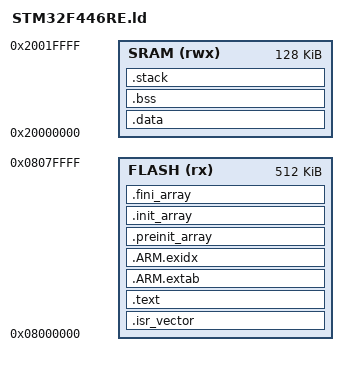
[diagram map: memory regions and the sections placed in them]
/*
 * STM32F446RE linker script for MAMBA-NIKE KAT test.
 *
 * Memory layout:
 *   FLASH: 512 KB (0x08000000)
 *   SRAM:  128 KB (0x20000000)
 *
 * Heap: 0 KB (all memory via static pools — no malloc on bare metal)
 * Stack: 8 KB
 */

MEMORY
{
    FLASH (rx) : ORIGIN = 0x08000000, LENGTH = 512K
    SRAM  (rwx): ORIGIN = 0x20000000, LENGTH = 128K
}

_estack = ORIGIN(SRAM) + LENGTH(SRAM);

SECTIONS
{
    .isr_vector :
    {
        KEEP(*(.isr_vector))
    } >FLASH

    .text :
    {
        *(.text*)
        *(.rodata*)
        KEEP(*(.init))
        KEEP(*(.fini))
    } >FLASH

    .ARM.extab : { *(.ARM.extab* .gnu.linkonce.armextab.*) } >FLASH
    .ARM.exidx : { *(.ARM.exidx*) } >FLASH

    .preinit_array :
    {
        PROVIDE_HIDDEN(__preinit_array_start = .);
        KEEP(*(.preinit_array*))
        PROVIDE_HIDDEN(__preinit_array_end = .);
    } >FLASH

    .init_array :
    {
        PROVIDE_HIDDEN(__init_array_start = .);
        KEEP(*(SORT(.init_array.*)))
        KEEP(*(.init_array*))
        PROVIDE_HIDDEN(__init_array_end = .);
    } >FLASH

    .fini_array :
    {
        PROVIDE_HIDDEN(__fini_array_start = .);
        KEEP(*(.fini_array*))
        KEEP(*(SORT(.fini_array.*)))
        PROVIDE_HIDDEN(__fini_array_end = .);
    } >FLASH

    _sidata = LOADADDR(.data);
    .data : AT(_sidata)
    {
        _sdata = .;
        *(.data*)
        _edata = .;
    } >SRAM

    .bss :
    {
        _sbss = .;
        *(.bss*)
        *(COMMON)
        _ebss = .;
    } >SRAM

    /* Reserve 8 KB for system stack */
    .stack (NOLOAD) :
    {
        . = ALIGN(8);
        _sstack = .;
        . = . + 8K;
        _estack_custom = .;
    } >SRAM
}
